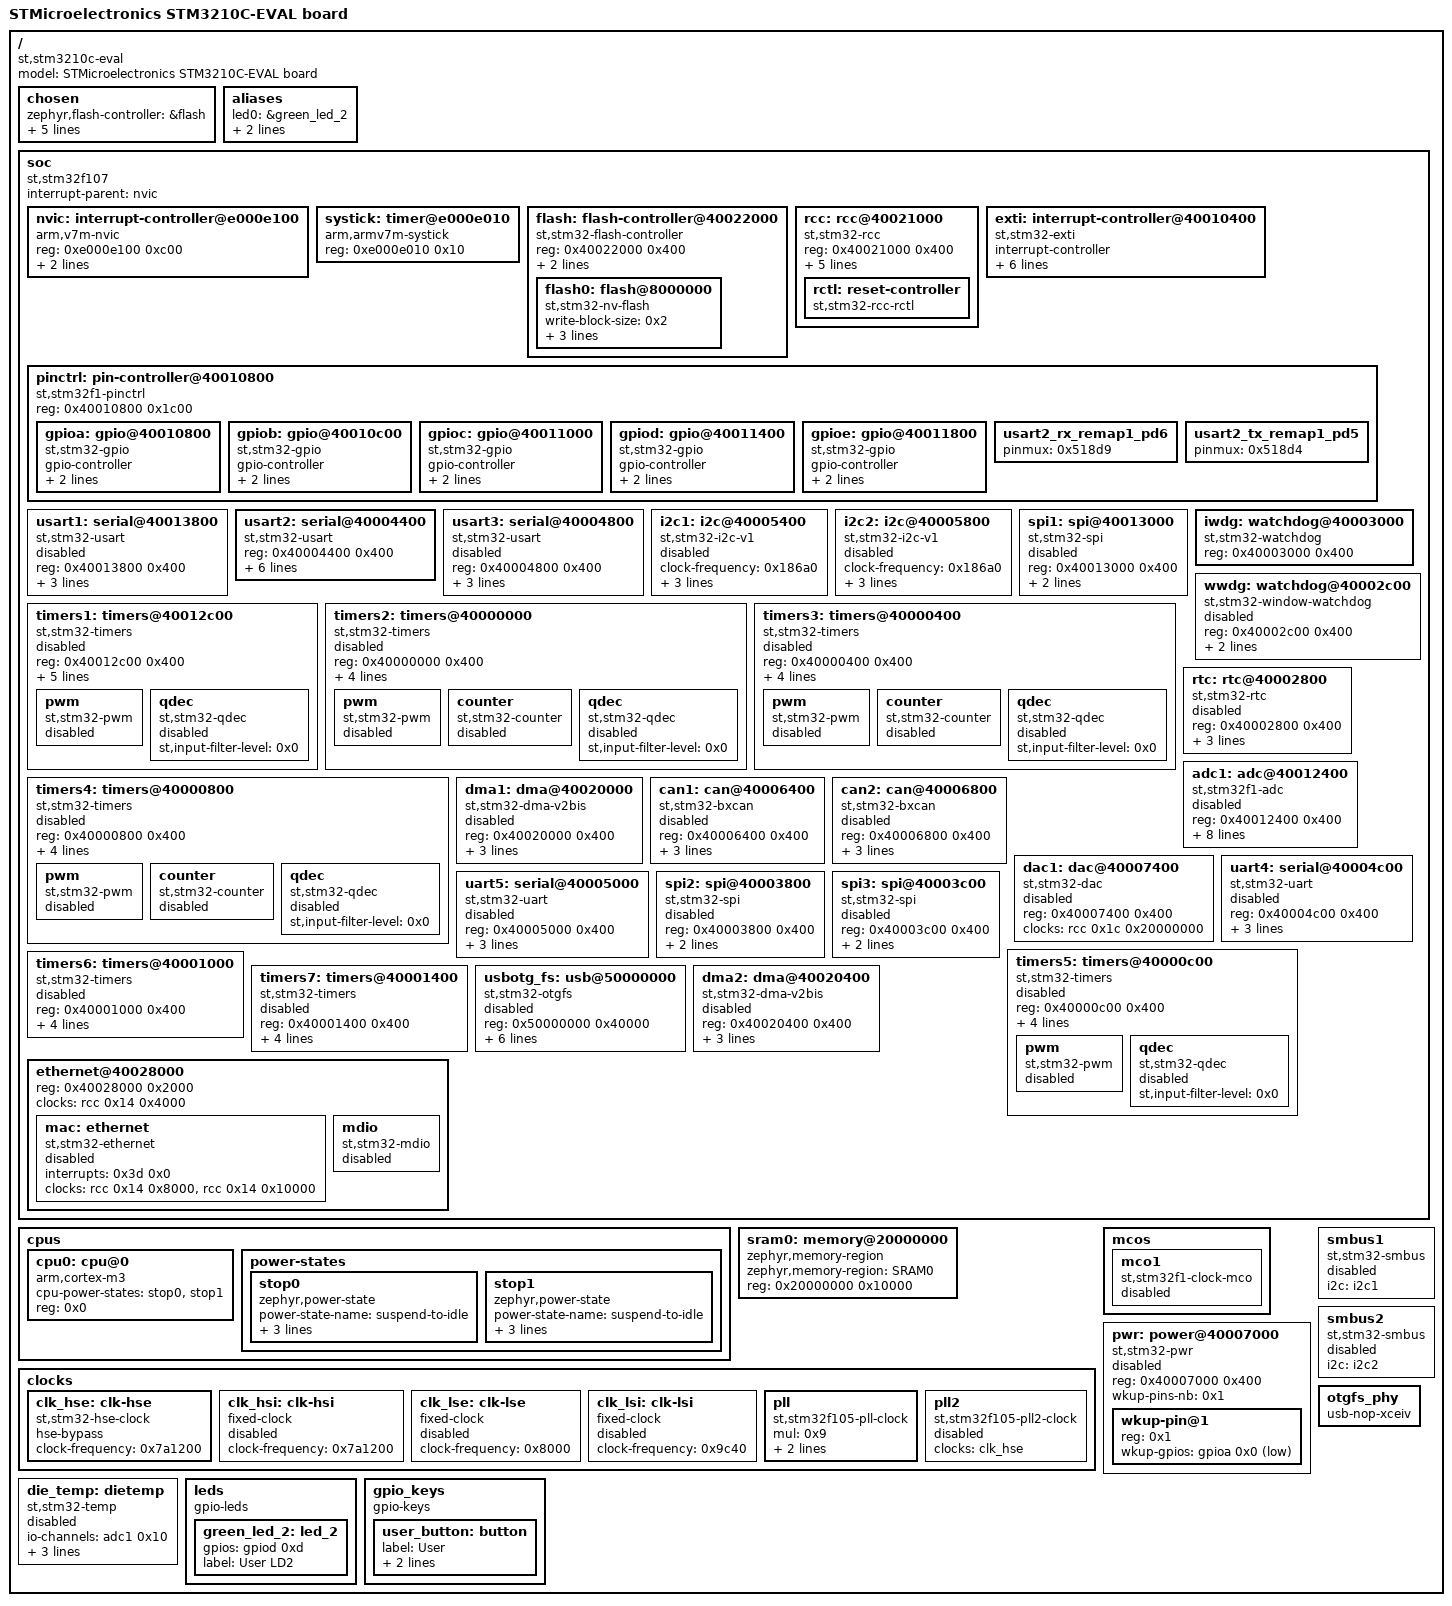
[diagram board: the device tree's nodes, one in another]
/dts-v1/;

/* node '/' defined in zephyr/dts/common/skeleton.dtsi:9 */
/ {
	#address-cells = < 0x1 >;                         /* in zephyr/dts/common/skeleton.dtsi:10 */
	#size-cells = < 0x1 >;                            /* in zephyr/dts/common/skeleton.dtsi:11 */
	model = "STMicroelectronics STM3210C-EVAL board"; /* in zephyr/boards/st/stm3210c_eval/stm3210c_eval.dts:13 */
	compatible = "st,stm3210c-eval";                  /* in zephyr/boards/st/stm3210c_eval/stm3210c_eval.dts:14 */

	/* node '/chosen' defined in zephyr/dts/common/skeleton.dtsi:13 */
	chosen {
		zephyr,flash-controller = &flash;  /* in zephyr/dts/arm/st/f1/stm32f1.dtsi:25 */
		zephyr,cortex-m-idle-timer = &rtc; /* in zephyr/dts/arm/st/f1/stm32f1.dtsi:26 */
		zephyr,console = &usart2;          /* in zephyr/boards/st/stm3210c_eval/stm3210c_eval.dts:17 */
		zephyr,shell-uart = &usart2;       /* in zephyr/boards/st/stm3210c_eval/stm3210c_eval.dts:18 */
		zephyr,sram = &sram0;              /* in zephyr/boards/st/stm3210c_eval/stm3210c_eval.dts:19 */
		zephyr,flash = &flash0;            /* in zephyr/boards/st/stm3210c_eval/stm3210c_eval.dts:20 */
	};

	/* node '/aliases' defined in zephyr/dts/common/skeleton.dtsi:15 */
	aliases {
		led0 = &green_led_2; /* in zephyr/boards/st/stm3210c_eval/stm3210c_eval.dts:43 */
		sw0 = &user_button;  /* in zephyr/boards/st/stm3210c_eval/stm3210c_eval.dts:44 */
		watchdog0 = &iwdg;   /* in zephyr/boards/st/stm3210c_eval/stm3210c_eval.dts:45 */
	};

	/* node '/soc' defined in zephyr/dts/arm/armv7-m.dtsi:6 */
	soc {
		#address-cells = < 0x1 >;     /* in zephyr/dts/arm/armv7-m.dtsi:7 */
		#size-cells = < 0x1 >;        /* in zephyr/dts/arm/armv7-m.dtsi:8 */
		interrupt-parent = < &nvic >; /* in zephyr/dts/arm/armv7-m.dtsi:10 */
		ranges;                       /* in zephyr/dts/arm/armv7-m.dtsi:11 */
		compatible = "st,stm32f107",
		             "st,stm32f1",
		             "simple-bus";    /* in zephyr/dts/arm/st/f1/stm32f107.dtsi:11 */

		/* node '/soc/interrupt-controller@e000e100' defined in zephyr/dts/arm/armv7-m.dtsi:13 */
		nvic: interrupt-controller@e000e100 {
			#address-cells = < 0x1 >;            /* in zephyr/dts/arm/armv7-m.dtsi:14 */
			compatible = "arm,v7m-nvic";         /* in zephyr/dts/arm/armv7-m.dtsi:15 */
			reg = < 0xe000e100 0xc00 >;          /* in zephyr/dts/arm/armv7-m.dtsi:16 */
			interrupt-controller;                /* in zephyr/dts/arm/armv7-m.dtsi:17 */
			#interrupt-cells = < 0x2 >;          /* in zephyr/dts/arm/armv7-m.dtsi:18 */
			arm,num-irq-priority-bits = < 0x4 >; /* in zephyr/dts/arm/st/f1/stm32f1.dtsi:461 */
			phandle = < 0x1 >;                   /* in zephyr/dts/arm/armv7-m.dtsi:10 */
		};

		/* node '/soc/timer@e000e010' defined in zephyr/dts/arm/armv7-m.dtsi:21 */
		systick: timer@e000e010 {
			compatible = "arm,armv7m-systick"; /* in zephyr/dts/arm/armv7-m.dtsi:22 */
			reg = < 0xe000e010 0x10 >;         /* in zephyr/dts/arm/armv7-m.dtsi:23 */
		};

		/* node '/soc/flash-controller@40022000' defined in zephyr/dts/arm/st/f1/stm32f1.dtsi:107 */
		flash: flash-controller@40022000 {
			compatible = "st,stm32-flash-controller",
			             "st,stm32f1-flash-controller"; /* in zephyr/dts/arm/st/f1/stm32f1.dtsi:108 */
			reg = < 0x40022000 0x400 >;                 /* in zephyr/dts/arm/st/f1/stm32f1.dtsi:109 */
			interrupts = < 0x3 0x0 >;                   /* in zephyr/dts/arm/st/f1/stm32f1.dtsi:110 */
			clocks = < &rcc 0x14 0x10 >;                /* in zephyr/dts/arm/st/f1/stm32f1.dtsi:111 */
			#address-cells = < 0x1 >;                   /* in zephyr/dts/arm/st/f1/stm32f1.dtsi:113 */
			#size-cells = < 0x1 >;                      /* in zephyr/dts/arm/st/f1/stm32f1.dtsi:114 */

			/* node '/soc/flash-controller@40022000/flash@8000000' defined in zephyr/dts/arm/st/f1/stm32f1.dtsi:116 */
			flash0: flash@8000000 {
				compatible = "st,stm32-nv-flash",
				             "soc-nv-flash";      /* in zephyr/dts/arm/st/f1/stm32f1.dtsi:117 */
				write-block-size = < 0x2 >;       /* in zephyr/dts/arm/st/f1/stm32f1.dtsi:119 */
				max-erase-time = < 0x28 >;        /* in zephyr/dts/arm/st/f1/stm32f1.dtsi:121 */
				erase-block-size = < 0x800 >;     /* in zephyr/dts/arm/st/f1/stm32f105.dtsi:34 */
				reg = < 0x8000000 0x40000 >;      /* in zephyr/dts/arm/st/f1/stm32f107Xc.dtsi:17 */
			};
		};

		/* node '/soc/rcc@40021000' defined in zephyr/dts/arm/st/f1/stm32f1.dtsi:125 */
		rcc: rcc@40021000 {
			compatible = "st,stm32-rcc";     /* in zephyr/dts/arm/st/f1/stm32f1.dtsi:126 */
			#clock-cells = < 0x2 >;          /* in zephyr/dts/arm/st/f1/stm32f1.dtsi:127 */
			reg = < 0x40021000 0x400 >;      /* in zephyr/dts/arm/st/f1/stm32f1.dtsi:128 */
			clocks = < &pll >;               /* in zephyr/boards/st/stm3210c_eval/stm3210c_eval.dts:63 */
			clock-frequency = < 0x44aa200 >; /* in zephyr/boards/st/stm3210c_eval/stm3210c_eval.dts:64 */
			ahb-prescaler = < 0x1 >;         /* in zephyr/boards/st/stm3210c_eval/stm3210c_eval.dts:65 */
			apb1-prescaler = < 0x2 >;        /* in zephyr/boards/st/stm3210c_eval/stm3210c_eval.dts:66 */
			apb2-prescaler = < 0x1 >;        /* in zephyr/boards/st/stm3210c_eval/stm3210c_eval.dts:67 */
			phandle = < 0x2 >;               /* in zephyr/dts/arm/st/f1/stm32f1.dtsi:111 */

			/* node '/soc/rcc@40021000/reset-controller' defined in zephyr/dts/arm/st/f1/stm32f1.dtsi:130 */
			rctl: reset-controller {
				compatible = "st,stm32-rcc-rctl"; /* in zephyr/dts/arm/st/f1/stm32f1.dtsi:131 */
				#reset-cells = < 0x1 >;           /* in zephyr/dts/arm/st/f1/stm32f1.dtsi:132 */
				phandle = < 0x4 >;                /* in zephyr/dts/arm/st/f1/stm32f1.dtsi:202 */
			};
		};

		/* node '/soc/interrupt-controller@40010400' defined in zephyr/dts/arm/st/f1/stm32f1.dtsi:136 */
		exti: interrupt-controller@40010400 {
			compatible = "st,stm32-exti";  /* in zephyr/dts/arm/st/f1/stm32f1.dtsi:137 */
			interrupt-controller;          /* in zephyr/dts/arm/st/f1/stm32f1.dtsi:138 */
			#interrupt-cells = < 0x1 >;    /* in zephyr/dts/arm/st/f1/stm32f1.dtsi:139 */
			#address-cells = < 0x0 >;      /* in zephyr/dts/arm/st/f1/stm32f1.dtsi:140 */
			reg = < 0x40010400 0x400 >;    /* in zephyr/dts/arm/st/f1/stm32f1.dtsi:141 */
			num-lines = < 0x20 >;          /* in zephyr/dts/arm/st/f1/stm32f1.dtsi:142 */
			interrupts = < 0x6 0x0 >,
			             < 0x7 0x0 >,
			             < 0x8 0x0 >,
			             < 0x9 0x0 >,
			             < 0xa 0x0 >,
			             < 0x17 0x0 >,
			             < 0x28 0x0 >;     /* in zephyr/dts/arm/st/f1/stm32f1.dtsi:143 */
			interrupt-names = "line0",
			                  "line1",
			                  "line2",
			                  "line3",
			                  "line4",
			                  "line5-9",
			                  "line10-15"; /* in zephyr/dts/arm/st/f1/stm32f1.dtsi:145 */
			line-ranges = < 0x0 0x1 >,
			              < 0x1 0x1 >,
			              < 0x2 0x1 >,
			              < 0x3 0x1 >,
			              < 0x4 0x1 >,
			              < 0x5 0x5 >,
			              < 0xa 0x6 >;     /* in zephyr/dts/arm/st/f1/stm32f1.dtsi:147 */
		};

		/* node '/soc/pin-controller@40010800' defined in zephyr/dts/arm/st/f1/stm32f1.dtsi:151 */
		pinctrl: pin-controller@40010800 {
			compatible = "st,stm32f1-pinctrl"; /* in zephyr/dts/arm/st/f1/stm32f1.dtsi:152 */
			#address-cells = < 0x1 >;          /* in zephyr/dts/arm/st/f1/stm32f1.dtsi:153 */
			#size-cells = < 0x1 >;             /* in zephyr/dts/arm/st/f1/stm32f1.dtsi:154 */
			reg = < 0x40010800 0x1c00 >;       /* in zephyr/dts/arm/st/f1/stm32f1.dtsi:155 */

			/* node '/soc/pin-controller@40010800/gpio@40010800' defined in zephyr/dts/arm/st/f1/stm32f1.dtsi:157 */
			gpioa: gpio@40010800 {
				compatible = "st,stm32-gpio"; /* in zephyr/dts/arm/st/f1/stm32f1.dtsi:158 */
				gpio-controller;              /* in zephyr/dts/arm/st/f1/stm32f1.dtsi:159 */
				#gpio-cells = < 0x2 >;        /* in zephyr/dts/arm/st/f1/stm32f1.dtsi:160 */
				reg = < 0x40010800 0x400 >;   /* in zephyr/dts/arm/st/f1/stm32f1.dtsi:161 */
				clocks = < &rcc 0x18 0x4 >;   /* in zephyr/dts/arm/st/f1/stm32f1.dtsi:162 */
				phandle = < 0xb >;            /* in zephyr/dts/arm/st/f1/stm32f1.dtsi:430 */
			};

			/* node '/soc/pin-controller@40010800/gpio@40010c00' defined in zephyr/dts/arm/st/f1/stm32f1.dtsi:165 */
			gpiob: gpio@40010c00 {
				compatible = "st,stm32-gpio"; /* in zephyr/dts/arm/st/f1/stm32f1.dtsi:166 */
				gpio-controller;              /* in zephyr/dts/arm/st/f1/stm32f1.dtsi:167 */
				#gpio-cells = < 0x2 >;        /* in zephyr/dts/arm/st/f1/stm32f1.dtsi:168 */
				reg = < 0x40010c00 0x400 >;   /* in zephyr/dts/arm/st/f1/stm32f1.dtsi:169 */
				clocks = < &rcc 0x18 0x8 >;   /* in zephyr/dts/arm/st/f1/stm32f1.dtsi:170 */
				phandle = < 0x10 >;           /* in zephyr/boards/st/stm3210c_eval/stm3210c_eval.dts:37 */
			};

			/* node '/soc/pin-controller@40010800/gpio@40011000' defined in zephyr/dts/arm/st/f1/stm32f1.dtsi:173 */
			gpioc: gpio@40011000 {
				compatible = "st,stm32-gpio"; /* in zephyr/dts/arm/st/f1/stm32f1.dtsi:174 */
				gpio-controller;              /* in zephyr/dts/arm/st/f1/stm32f1.dtsi:175 */
				#gpio-cells = < 0x2 >;        /* in zephyr/dts/arm/st/f1/stm32f1.dtsi:176 */
				reg = < 0x40011000 0x400 >;   /* in zephyr/dts/arm/st/f1/stm32f1.dtsi:177 */
				clocks = < &rcc 0x18 0x10 >;  /* in zephyr/dts/arm/st/f1/stm32f1.dtsi:178 */
			};

			/* node '/soc/pin-controller@40010800/gpio@40011400' defined in zephyr/dts/arm/st/f1/stm32f1.dtsi:181 */
			gpiod: gpio@40011400 {
				compatible = "st,stm32-gpio"; /* in zephyr/dts/arm/st/f1/stm32f1.dtsi:182 */
				gpio-controller;              /* in zephyr/dts/arm/st/f1/stm32f1.dtsi:183 */
				#gpio-cells = < 0x2 >;        /* in zephyr/dts/arm/st/f1/stm32f1.dtsi:184 */
				reg = < 0x40011400 0x400 >;   /* in zephyr/dts/arm/st/f1/stm32f1.dtsi:185 */
				clocks = < &rcc 0x18 0x20 >;  /* in zephyr/dts/arm/st/f1/stm32f1.dtsi:186 */
				phandle = < 0xf >;            /* in zephyr/boards/st/stm3210c_eval/stm3210c_eval.dts:27 */
			};

			/* node '/soc/pin-controller@40010800/gpio@40011800' defined in zephyr/dts/arm/st/f1/stm32f1.dtsi:189 */
			gpioe: gpio@40011800 {
				compatible = "st,stm32-gpio"; /* in zephyr/dts/arm/st/f1/stm32f1.dtsi:190 */
				gpio-controller;              /* in zephyr/dts/arm/st/f1/stm32f1.dtsi:191 */
				#gpio-cells = < 0x2 >;        /* in zephyr/dts/arm/st/f1/stm32f1.dtsi:192 */
				reg = < 0x40011800 0x400 >;   /* in zephyr/dts/arm/st/f1/stm32f1.dtsi:193 */
				clocks = < &rcc 0x18 0x40 >;  /* in zephyr/dts/arm/st/f1/stm32f1.dtsi:194 */
			};

			/* node '/soc/pin-controller@40010800/usart2_rx_remap1_pd6' defined in modules/hal/stm32/dts/st/f1/stm32f107v(b-c)tx-pinctrl.dtsi:1537 */
			usart2_rx_remap1_pd6: usart2_rx_remap1_pd6 {
				pinmux = < 0x518d9 >; /* in modules/hal/stm32/dts/st/f1/stm32f107v(b-c)tx-pinctrl.dtsi:1538 */
				phandle = < 0x6 >;    /* in zephyr/boards/st/stm3210c_eval/stm3210c_eval.dts:71 */
			};

			/* node '/soc/pin-controller@40010800/usart2_tx_remap1_pd5' defined in modules/hal/stm32/dts/st/f1/stm32f107v(b-c)tx-pinctrl.dtsi:1575 */
			usart2_tx_remap1_pd5: usart2_tx_remap1_pd5 {
				pinmux = < 0x518d4 >; /* in modules/hal/stm32/dts/st/f1/stm32f107v(b-c)tx-pinctrl.dtsi:1576 */
				phandle = < 0x5 >;    /* in zephyr/boards/st/stm3210c_eval/stm3210c_eval.dts:71 */
			};
		};

		/* node '/soc/serial@40013800' defined in zephyr/dts/arm/st/f1/stm32f1.dtsi:198 */
		usart1: serial@40013800 {
			compatible = "st,stm32-usart",
			             "st,stm32-uart";  /* in zephyr/dts/arm/st/f1/stm32f1.dtsi:199 */
			reg = < 0x40013800 0x400 >;    /* in zephyr/dts/arm/st/f1/stm32f1.dtsi:200 */
			clocks = < &rcc 0x18 0x4000 >; /* in zephyr/dts/arm/st/f1/stm32f1.dtsi:201 */
			resets = < &rctl 0x18e >;      /* in zephyr/dts/arm/st/f1/stm32f1.dtsi:202 */
			interrupts = < 0x25 0x0 >;     /* in zephyr/dts/arm/st/f1/stm32f1.dtsi:203 */
			status = "disabled";           /* in zephyr/dts/arm/st/f1/stm32f1.dtsi:204 */
		};

		/* node '/soc/serial@40004400' defined in zephyr/dts/arm/st/f1/stm32f1.dtsi:207 */
		usart2: serial@40004400 {
			compatible = "st,stm32-usart",
			             "st,stm32-uart";                                /* in zephyr/dts/arm/st/f1/stm32f1.dtsi:208 */
			reg = < 0x40004400 0x400 >;                                  /* in zephyr/dts/arm/st/f1/stm32f1.dtsi:209 */
			clocks = < &rcc 0x1c 0x20000 >;                              /* in zephyr/dts/arm/st/f1/stm32f1.dtsi:210 */
			resets = < &rctl 0x211 >;                                    /* in zephyr/dts/arm/st/f1/stm32f1.dtsi:211 */
			interrupts = < 0x26 0x0 >;                                   /* in zephyr/dts/arm/st/f1/stm32f1.dtsi:212 */
			pinctrl-0 = < &usart2_tx_remap1_pd5 &usart2_rx_remap1_pd6 >; /* in zephyr/boards/st/stm3210c_eval/stm3210c_eval.dts:71 */
			pinctrl-names = "default";                                   /* in zephyr/boards/st/stm3210c_eval/stm3210c_eval.dts:72 */
			current-speed = < 0x1c200 >;                                 /* in zephyr/boards/st/stm3210c_eval/stm3210c_eval.dts:73 */
			status = "okay";                                             /* in zephyr/boards/st/stm3210c_eval/stm3210c_eval.dts:74 */
		};

		/* node '/soc/serial@40004800' defined in zephyr/dts/arm/st/f1/stm32f1.dtsi:216 */
		usart3: serial@40004800 {
			compatible = "st,stm32-usart",
			             "st,stm32-uart";   /* in zephyr/dts/arm/st/f1/stm32f1.dtsi:217 */
			reg = < 0x40004800 0x400 >;     /* in zephyr/dts/arm/st/f1/stm32f1.dtsi:218 */
			clocks = < &rcc 0x1c 0x40000 >; /* in zephyr/dts/arm/st/f1/stm32f1.dtsi:219 */
			resets = < &rctl 0x212 >;       /* in zephyr/dts/arm/st/f1/stm32f1.dtsi:220 */
			interrupts = < 0x27 0x0 >;      /* in zephyr/dts/arm/st/f1/stm32f1.dtsi:221 */
			status = "disabled";            /* in zephyr/dts/arm/st/f1/stm32f1.dtsi:222 */
		};

		/* node '/soc/i2c@40005400' defined in zephyr/dts/arm/st/f1/stm32f1.dtsi:225 */
		i2c1: i2c@40005400 {
			compatible = "st,stm32-i2c-v1";  /* in zephyr/dts/arm/st/f1/stm32f1.dtsi:226 */
			clock-frequency = < 0x186a0 >;   /* in zephyr/dts/arm/st/f1/stm32f1.dtsi:227 */
			#address-cells = < 0x1 >;        /* in zephyr/dts/arm/st/f1/stm32f1.dtsi:228 */
			#size-cells = < 0x0 >;           /* in zephyr/dts/arm/st/f1/stm32f1.dtsi:229 */
			reg = < 0x40005400 0x400 >;      /* in zephyr/dts/arm/st/f1/stm32f1.dtsi:230 */
			clocks = < &rcc 0x1c 0x200000 >; /* in zephyr/dts/arm/st/f1/stm32f1.dtsi:231 */
			interrupts = < 0x1f 0x0 >,
			             < 0x20 0x0 >;       /* in zephyr/dts/arm/st/f1/stm32f1.dtsi:232 */
			interrupt-names = "event",
			                  "error";       /* in zephyr/dts/arm/st/f1/stm32f1.dtsi:233 */
			status = "disabled";             /* in zephyr/dts/arm/st/f1/stm32f1.dtsi:234 */
			phandle = < 0xd >;               /* in zephyr/dts/arm/st/f1/stm32f1.dtsi:447 */
		};

		/* node '/soc/i2c@40005800' defined in zephyr/dts/arm/st/f1/stm32f1.dtsi:237 */
		i2c2: i2c@40005800 {
			compatible = "st,stm32-i2c-v1";  /* in zephyr/dts/arm/st/f1/stm32f1.dtsi:238 */
			clock-frequency = < 0x186a0 >;   /* in zephyr/dts/arm/st/f1/stm32f1.dtsi:239 */
			#address-cells = < 0x1 >;        /* in zephyr/dts/arm/st/f1/stm32f1.dtsi:240 */
			#size-cells = < 0x0 >;           /* in zephyr/dts/arm/st/f1/stm32f1.dtsi:241 */
			reg = < 0x40005800 0x400 >;      /* in zephyr/dts/arm/st/f1/stm32f1.dtsi:242 */
			clocks = < &rcc 0x1c 0x400000 >; /* in zephyr/dts/arm/st/f1/stm32f1.dtsi:243 */
			interrupts = < 0x21 0x0 >,
			             < 0x22 0x0 >;       /* in zephyr/dts/arm/st/f1/stm32f1.dtsi:244 */
			interrupt-names = "event",
			                  "error";       /* in zephyr/dts/arm/st/f1/stm32f1.dtsi:245 */
			status = "disabled";             /* in zephyr/dts/arm/st/f1/stm32f1.dtsi:246 */
			phandle = < 0xe >;               /* in zephyr/dts/arm/st/f1/stm32f1.dtsi:455 */
		};

		/* node '/soc/spi@40013000' defined in zephyr/dts/arm/st/f1/stm32f1.dtsi:249 */
		spi1: spi@40013000 {
			compatible = "st,stm32-spi";   /* in zephyr/dts/arm/st/f1/stm32f1.dtsi:250 */
			#address-cells = < 0x1 >;      /* in zephyr/dts/arm/st/f1/stm32f1.dtsi:251 */
			#size-cells = < 0x0 >;         /* in zephyr/dts/arm/st/f1/stm32f1.dtsi:252 */
			reg = < 0x40013000 0x400 >;    /* in zephyr/dts/arm/st/f1/stm32f1.dtsi:253 */
			clocks = < &rcc 0x18 0x1000 >; /* in zephyr/dts/arm/st/f1/stm32f1.dtsi:254 */
			interrupts = < 0x23 0x5 >;     /* in zephyr/dts/arm/st/f1/stm32f1.dtsi:255 */
			status = "disabled";           /* in zephyr/dts/arm/st/f1/stm32f1.dtsi:256 */
		};

		/* node '/soc/watchdog@40003000' defined in zephyr/dts/arm/st/f1/stm32f1.dtsi:259 */
		iwdg: watchdog@40003000 {
			compatible = "st,stm32-watchdog"; /* in zephyr/dts/arm/st/f1/stm32f1.dtsi:260 */
			reg = < 0x40003000 0x400 >;       /* in zephyr/dts/arm/st/f1/stm32f1.dtsi:261 */
			status = "okay";                  /* in zephyr/boards/st/stm3210c_eval/stm3210c_eval.dts:78 */
		};

		/* node '/soc/watchdog@40002c00' defined in zephyr/dts/arm/st/f1/stm32f1.dtsi:265 */
		wwdg: watchdog@40002c00 {
			compatible = "st,stm32-window-watchdog"; /* in zephyr/dts/arm/st/f1/stm32f1.dtsi:266 */
			reg = < 0x40002c00 0x400 >;              /* in zephyr/dts/arm/st/f1/stm32f1.dtsi:267 */
			clocks = < &rcc 0x1c 0x800 >;            /* in zephyr/dts/arm/st/f1/stm32f1.dtsi:268 */
			interrupts = < 0x0 0x7 >;                /* in zephyr/dts/arm/st/f1/stm32f1.dtsi:269 */
			status = "disabled";                     /* in zephyr/dts/arm/st/f1/stm32f1.dtsi:270 */
		};

		/* node '/soc/timers@40012c00' defined in zephyr/dts/arm/st/f1/stm32f1.dtsi:273 */
		timers1: timers@40012c00 {
			compatible = "st,stm32-timers"; /* in zephyr/dts/arm/st/f1/stm32f1.dtsi:274 */
			reg = < 0x40012c00 0x400 >;     /* in zephyr/dts/arm/st/f1/stm32f1.dtsi:275 */
			clocks = < &rcc 0x18 0x800 >,
			         < &rcc 0x9 0xff >;     /* in zephyr/dts/arm/st/f1/stm32f1.dtsi:276 */
			resets = < &rctl 0x18b >;       /* in zephyr/dts/arm/st/f1/stm32f1.dtsi:278 */
			interrupts = < 0x18 0x0 >,
			             < 0x19 0x0 >,
			             < 0x1a 0x0 >,
			             < 0x1b 0x0 >;      /* in zephyr/dts/arm/st/f1/stm32f1.dtsi:279 */
			interrupt-names = "brk",
			                  "up",
			                  "trgcom",
			                  "cc";         /* in zephyr/dts/arm/st/f1/stm32f1.dtsi:280 */
			st,prescaler = < 0x0 >;         /* in zephyr/dts/arm/st/f1/stm32f1.dtsi:281 */
			status = "disabled";            /* in zephyr/dts/arm/st/f1/stm32f1.dtsi:282 */

			/* node '/soc/timers@40012c00/pwm' defined in zephyr/dts/arm/st/f1/stm32f1.dtsi:284 */
			pwm {
				compatible = "st,stm32-pwm"; /* in zephyr/dts/arm/st/f1/stm32f1.dtsi:285 */
				status = "disabled";         /* in zephyr/dts/arm/st/f1/stm32f1.dtsi:286 */
				#pwm-cells = < 0x3 >;        /* in zephyr/dts/arm/st/f1/stm32f1.dtsi:287 */
			};

			/* node '/soc/timers@40012c00/qdec' defined in zephyr/dts/arm/st/f1/stm32f1.dtsi:290 */
			qdec {
				compatible = "st,stm32-qdec";    /* in zephyr/dts/arm/st/f1/stm32f1.dtsi:291 */
				st,input-filter-level = < 0x0 >; /* in zephyr/dts/arm/st/f1/stm32f1.dtsi:292 */
				status = "disabled";             /* in zephyr/dts/arm/st/f1/stm32f1.dtsi:293 */
			};
		};

		/* node '/soc/timers@40000000' defined in zephyr/dts/arm/st/f1/stm32f1.dtsi:297 */
		timers2: timers@40000000 {
			compatible = "st,stm32-timers"; /* in zephyr/dts/arm/st/f1/stm32f1.dtsi:298 */
			reg = < 0x40000000 0x400 >;     /* in zephyr/dts/arm/st/f1/stm32f1.dtsi:299 */
			clocks = < &rcc 0x1c 0x1 >,
			         < &rcc 0x8 0xff >;     /* in zephyr/dts/arm/st/f1/stm32f1.dtsi:300 */
			resets = < &rctl 0x200 >;       /* in zephyr/dts/arm/st/f1/stm32f1.dtsi:302 */
			interrupts = < 0x1c 0x0 >;      /* in zephyr/dts/arm/st/f1/stm32f1.dtsi:303 */
			interrupt-names = "global";     /* in zephyr/dts/arm/st/f1/stm32f1.dtsi:304 */
			st,prescaler = < 0x0 >;         /* in zephyr/dts/arm/st/f1/stm32f1.dtsi:305 */
			status = "disabled";            /* in zephyr/dts/arm/st/f1/stm32f1.dtsi:306 */

			/* node '/soc/timers@40000000/pwm' defined in zephyr/dts/arm/st/f1/stm32f1.dtsi:308 */
			pwm {
				compatible = "st,stm32-pwm"; /* in zephyr/dts/arm/st/f1/stm32f1.dtsi:309 */
				status = "disabled";         /* in zephyr/dts/arm/st/f1/stm32f1.dtsi:310 */
				#pwm-cells = < 0x3 >;        /* in zephyr/dts/arm/st/f1/stm32f1.dtsi:311 */
			};

			/* node '/soc/timers@40000000/counter' defined in zephyr/dts/arm/st/f1/stm32f1.dtsi:314 */
			counter {
				compatible = "st,stm32-counter"; /* in zephyr/dts/arm/st/f1/stm32f1.dtsi:315 */
				status = "disabled";             /* in zephyr/dts/arm/st/f1/stm32f1.dtsi:316 */
			};

			/* node '/soc/timers@40000000/qdec' defined in zephyr/dts/arm/st/f1/stm32f1.dtsi:319 */
			qdec {
				compatible = "st,stm32-qdec";    /* in zephyr/dts/arm/st/f1/stm32f1.dtsi:320 */
				st,input-filter-level = < 0x0 >; /* in zephyr/dts/arm/st/f1/stm32f1.dtsi:321 */
				status = "disabled";             /* in zephyr/dts/arm/st/f1/stm32f1.dtsi:322 */
			};
		};

		/* node '/soc/timers@40000400' defined in zephyr/dts/arm/st/f1/stm32f1.dtsi:326 */
		timers3: timers@40000400 {
			compatible = "st,stm32-timers"; /* in zephyr/dts/arm/st/f1/stm32f1.dtsi:327 */
			reg = < 0x40000400 0x400 >;     /* in zephyr/dts/arm/st/f1/stm32f1.dtsi:328 */
			clocks = < &rcc 0x1c 0x2 >,
			         < &rcc 0x8 0xff >;     /* in zephyr/dts/arm/st/f1/stm32f1.dtsi:329 */
			resets = < &rctl 0x201 >;       /* in zephyr/dts/arm/st/f1/stm32f1.dtsi:331 */
			interrupts = < 0x1d 0x0 >;      /* in zephyr/dts/arm/st/f1/stm32f1.dtsi:332 */
			interrupt-names = "global";     /* in zephyr/dts/arm/st/f1/stm32f1.dtsi:333 */
			st,prescaler = < 0x0 >;         /* in zephyr/dts/arm/st/f1/stm32f1.dtsi:334 */
			status = "disabled";            /* in zephyr/dts/arm/st/f1/stm32f1.dtsi:335 */

			/* node '/soc/timers@40000400/pwm' defined in zephyr/dts/arm/st/f1/stm32f1.dtsi:337 */
			pwm {
				compatible = "st,stm32-pwm"; /* in zephyr/dts/arm/st/f1/stm32f1.dtsi:338 */
				status = "disabled";         /* in zephyr/dts/arm/st/f1/stm32f1.dtsi:339 */
				#pwm-cells = < 0x3 >;        /* in zephyr/dts/arm/st/f1/stm32f1.dtsi:340 */
			};

			/* node '/soc/timers@40000400/counter' defined in zephyr/dts/arm/st/f1/stm32f1.dtsi:343 */
			counter {
				compatible = "st,stm32-counter"; /* in zephyr/dts/arm/st/f1/stm32f1.dtsi:344 */
				status = "disabled";             /* in zephyr/dts/arm/st/f1/stm32f1.dtsi:345 */
			};

			/* node '/soc/timers@40000400/qdec' defined in zephyr/dts/arm/st/f1/stm32f1.dtsi:348 */
			qdec {
				compatible = "st,stm32-qdec";    /* in zephyr/dts/arm/st/f1/stm32f1.dtsi:349 */
				st,input-filter-level = < 0x0 >; /* in zephyr/dts/arm/st/f1/stm32f1.dtsi:350 */
				status = "disabled";             /* in zephyr/dts/arm/st/f1/stm32f1.dtsi:351 */
			};
		};

		/* node '/soc/timers@40000800' defined in zephyr/dts/arm/st/f1/stm32f1.dtsi:355 */
		timers4: timers@40000800 {
			compatible = "st,stm32-timers"; /* in zephyr/dts/arm/st/f1/stm32f1.dtsi:356 */
			reg = < 0x40000800 0x400 >;     /* in zephyr/dts/arm/st/f1/stm32f1.dtsi:357 */
			clocks = < &rcc 0x1c 0x4 >,
			         < &rcc 0x8 0xff >;     /* in zephyr/dts/arm/st/f1/stm32f1.dtsi:358 */
			resets = < &rctl 0x202 >;       /* in zephyr/dts/arm/st/f1/stm32f1.dtsi:360 */
			interrupts = < 0x1e 0x0 >;      /* in zephyr/dts/arm/st/f1/stm32f1.dtsi:361 */
			interrupt-names = "global";     /* in zephyr/dts/arm/st/f1/stm32f1.dtsi:362 */
			st,prescaler = < 0x0 >;         /* in zephyr/dts/arm/st/f1/stm32f1.dtsi:363 */
			status = "disabled";            /* in zephyr/dts/arm/st/f1/stm32f1.dtsi:364 */

			/* node '/soc/timers@40000800/pwm' defined in zephyr/dts/arm/st/f1/stm32f1.dtsi:366 */
			pwm {
				compatible = "st,stm32-pwm"; /* in zephyr/dts/arm/st/f1/stm32f1.dtsi:367 */
				status = "disabled";         /* in zephyr/dts/arm/st/f1/stm32f1.dtsi:368 */
				#pwm-cells = < 0x3 >;        /* in zephyr/dts/arm/st/f1/stm32f1.dtsi:369 */
			};

			/* node '/soc/timers@40000800/counter' defined in zephyr/dts/arm/st/f1/stm32f1.dtsi:372 */
			counter {
				compatible = "st,stm32-counter"; /* in zephyr/dts/arm/st/f1/stm32f1.dtsi:373 */
				status = "disabled";             /* in zephyr/dts/arm/st/f1/stm32f1.dtsi:374 */
			};

			/* node '/soc/timers@40000800/qdec' defined in zephyr/dts/arm/st/f1/stm32f1.dtsi:377 */
			qdec {
				compatible = "st,stm32-qdec";    /* in zephyr/dts/arm/st/f1/stm32f1.dtsi:378 */
				st,input-filter-level = < 0x0 >; /* in zephyr/dts/arm/st/f1/stm32f1.dtsi:379 */
				status = "disabled";             /* in zephyr/dts/arm/st/f1/stm32f1.dtsi:380 */
			};
		};

		/* node '/soc/rtc@40002800' defined in zephyr/dts/arm/st/f1/stm32f1.dtsi:384 */
		rtc: rtc@40002800 {
			compatible = "st,stm32-rtc";       /* in zephyr/dts/arm/st/f1/stm32f1.dtsi:385 */
			reg = < 0x40002800 0x400 >;        /* in zephyr/dts/arm/st/f1/stm32f1.dtsi:386 */
			interrupts = < 0x29 0x0 >;         /* in zephyr/dts/arm/st/f1/stm32f1.dtsi:387 */
			clocks = < &rcc 0x1c 0x10000000 >; /* in zephyr/dts/arm/st/f1/stm32f1.dtsi:388 */
			prescaler = < 0x8000 >;            /* in zephyr/dts/arm/st/f1/stm32f1.dtsi:389 */
			status = "disabled";               /* in zephyr/dts/arm/st/f1/stm32f1.dtsi:390 */
		};

		/* node '/soc/adc@40012400' defined in zephyr/dts/arm/st/f1/stm32f1.dtsi:393 */
		adc1: adc@40012400 {
			compatible = "st,stm32f1-adc",
			             "st,stm32-adc";                               /* in zephyr/dts/arm/st/f1/stm32f1.dtsi:394 */
			reg = < 0x40012400 0x400 >;                                /* in zephyr/dts/arm/st/f1/stm32f1.dtsi:395 */
			clocks = < &rcc 0x18 0x200 >;                              /* in zephyr/dts/arm/st/f1/stm32f1.dtsi:396 */
			clock-names = "adcx";                                      /* in zephyr/dts/arm/st/f1/stm32f1.dtsi:397 */
			interrupts = < 0x12 0x0 >;                                 /* in zephyr/dts/arm/st/f1/stm32f1.dtsi:398 */
			#io-channel-cells = < 0x1 >;                               /* in zephyr/dts/arm/st/f1/stm32f1.dtsi:399 */
			resolutions = < 0x6000ff >;                                /* in zephyr/dts/arm/st/f1/stm32f1.dtsi:400 */
			sampling-times = < 0x2 0x8 0xe 0x1d 0x2a 0x38 0x48 0xf0 >; /* in zephyr/dts/arm/st/f1/stm32f1.dtsi:401 */
			st,adc-sequencer = "programmable";                         /* in zephyr/dts/arm/st/f1/stm32f1.dtsi:402 */
			st,adc-oversampler = "none";                               /* in zephyr/dts/arm/st/f1/stm32f1.dtsi:403 */
			st,adc-internal-regulator = "none";                        /* in zephyr/dts/arm/st/f1/stm32f1.dtsi:404 */
			status = "disabled";                                       /* in zephyr/dts/arm/st/f1/stm32f1.dtsi:405 */
			phandle = < 0xc >;                                         /* in zephyr/dts/arm/st/f1/stm32f1.dtsi:436 */
		};

		/* node '/soc/dma@40020000' defined in zephyr/dts/arm/st/f1/stm32f1.dtsi:408 */
		dma1: dma@40020000 {
			compatible = "st,stm32-dma-v2bis";                                          /* in zephyr/dts/arm/st/f1/stm32f1.dtsi:409 */
			#dma-cells = < 0x2 >;                                                       /* in zephyr/dts/arm/st/f1/stm32f1.dtsi:410 */
			reg = < 0x40020000 0x400 >;                                                 /* in zephyr/dts/arm/st/f1/stm32f1.dtsi:411 */
			clocks = < &rcc 0x14 0x1 >;                                                 /* in zephyr/dts/arm/st/f1/stm32f1.dtsi:412 */
			interrupts = < 0xb 0x0 0xc 0x0 0xd 0x0 0xe 0x0 0xf 0x0 0x10 0x0 0x11 0x0 >; /* in zephyr/dts/arm/st/f1/stm32f1.dtsi:413 */
			status = "disabled";                                                        /* in zephyr/dts/arm/st/f1/stm32f1.dtsi:414 */
		};

		/* node '/soc/can@40006400' defined in zephyr/dts/arm/st/f1/stm32f105.dtsi:38 */
		can1: can@40006400 {
			compatible = "st,stm32-bxcan";    /* in zephyr/dts/arm/st/f1/stm32f105.dtsi:39 */
			reg = < 0x40006400 0x400 >;       /* in zephyr/dts/arm/st/f1/stm32f105.dtsi:40 */
			interrupts = < 0x13 0x0 >,
			             < 0x14 0x0 >,
			             < 0x15 0x0 >,
			             < 0x16 0x0 >;        /* in zephyr/dts/arm/st/f1/stm32f105.dtsi:41 */
			interrupt-names = "TX",
			                  "RX0",
			                  "RX1",
			                  "SCE";          /* in zephyr/dts/arm/st/f1/stm32f105.dtsi:42 */
			clocks = < &rcc 0x1c 0x2000000 >; /* in zephyr/dts/arm/st/f1/stm32f105.dtsi:43 */
			status = "disabled";              /* in zephyr/dts/arm/st/f1/stm32f105.dtsi:44 */
		};

		/* node '/soc/can@40006800' defined in zephyr/dts/arm/st/f1/stm32f105.dtsi:47 */
		can2: can@40006800 {
			compatible = "st,stm32-bxcan";    /* in zephyr/dts/arm/st/f1/stm32f105.dtsi:48 */
			reg = < 0x40006800 0x400 >;       /* in zephyr/dts/arm/st/f1/stm32f105.dtsi:49 */
			interrupts = < 0x3f 0x0 >,
			             < 0x40 0x0 >,
			             < 0x41 0x0 >,
			             < 0x42 0x0 >;        /* in zephyr/dts/arm/st/f1/stm32f105.dtsi:50 */
			interrupt-names = "TX",
			                  "RX0",
			                  "RX1",
			                  "SCE";          /* in zephyr/dts/arm/st/f1/stm32f105.dtsi:51 */
			clocks = < &rcc 0x1c 0x6000000 >; /* in zephyr/dts/arm/st/f1/stm32f105.dtsi:53 */
			status = "disabled";              /* in zephyr/dts/arm/st/f1/stm32f105.dtsi:54 */
		};

		/* node '/soc/dac@40007400' defined in zephyr/dts/arm/st/f1/stm32f105.dtsi:57 */
		dac1: dac@40007400 {
			compatible = "st,stm32-dac";       /* in zephyr/dts/arm/st/f1/stm32f105.dtsi:58 */
			reg = < 0x40007400 0x400 >;        /* in zephyr/dts/arm/st/f1/stm32f105.dtsi:59 */
			clocks = < &rcc 0x1c 0x20000000 >; /* in zephyr/dts/arm/st/f1/stm32f105.dtsi:60 */
			status = "disabled";               /* in zephyr/dts/arm/st/f1/stm32f105.dtsi:61 */
			#io-channel-cells = < 0x1 >;       /* in zephyr/dts/arm/st/f1/stm32f105.dtsi:62 */
		};

		/* node '/soc/serial@40004c00' defined in zephyr/dts/arm/st/f1/stm32f105.dtsi:65 */
		uart4: serial@40004c00 {
			compatible = "st,stm32-uart";   /* in zephyr/dts/arm/st/f1/stm32f105.dtsi:66 */
			reg = < 0x40004c00 0x400 >;     /* in zephyr/dts/arm/st/f1/stm32f105.dtsi:67 */
			clocks = < &rcc 0x1c 0x80000 >; /* in zephyr/dts/arm/st/f1/stm32f105.dtsi:68 */
			resets = < &rctl 0x213 >;       /* in zephyr/dts/arm/st/f1/stm32f105.dtsi:69 */
			interrupts = < 0x34 0x0 >;      /* in zephyr/dts/arm/st/f1/stm32f105.dtsi:70 */
			status = "disabled";            /* in zephyr/dts/arm/st/f1/stm32f105.dtsi:71 */
		};

		/* node '/soc/serial@40005000' defined in zephyr/dts/arm/st/f1/stm32f105.dtsi:74 */
		uart5: serial@40005000 {
			compatible = "st,stm32-uart";    /* in zephyr/dts/arm/st/f1/stm32f105.dtsi:75 */
			reg = < 0x40005000 0x400 >;      /* in zephyr/dts/arm/st/f1/stm32f105.dtsi:76 */
			clocks = < &rcc 0x1c 0x100000 >; /* in zephyr/dts/arm/st/f1/stm32f105.dtsi:77 */
			resets = < &rctl 0x214 >;        /* in zephyr/dts/arm/st/f1/stm32f105.dtsi:78 */
			interrupts = < 0x35 0x0 >;       /* in zephyr/dts/arm/st/f1/stm32f105.dtsi:79 */
			status = "disabled";             /* in zephyr/dts/arm/st/f1/stm32f105.dtsi:80 */
		};

		/* node '/soc/spi@40003800' defined in zephyr/dts/arm/st/f1/stm32f105.dtsi:83 */
		spi2: spi@40003800 {
			compatible = "st,stm32-spi";   /* in zephyr/dts/arm/st/f1/stm32f105.dtsi:84 */
			#address-cells = < 0x1 >;      /* in zephyr/dts/arm/st/f1/stm32f105.dtsi:85 */
			#size-cells = < 0x0 >;         /* in zephyr/dts/arm/st/f1/stm32f105.dtsi:86 */
			reg = < 0x40003800 0x400 >;    /* in zephyr/dts/arm/st/f1/stm32f105.dtsi:87 */
			clocks = < &rcc 0x1c 0x4000 >; /* in zephyr/dts/arm/st/f1/stm32f105.dtsi:88 */
			interrupts = < 0x24 0x5 >;     /* in zephyr/dts/arm/st/f1/stm32f105.dtsi:89 */
			status = "disabled";           /* in zephyr/dts/arm/st/f1/stm32f105.dtsi:90 */
		};

		/* node '/soc/spi@40003c00' defined in zephyr/dts/arm/st/f1/stm32f105.dtsi:93 */
		spi3: spi@40003c00 {
			compatible = "st,stm32-spi";   /* in zephyr/dts/arm/st/f1/stm32f105.dtsi:94 */
			#address-cells = < 0x1 >;      /* in zephyr/dts/arm/st/f1/stm32f105.dtsi:95 */
			#size-cells = < 0x0 >;         /* in zephyr/dts/arm/st/f1/stm32f105.dtsi:96 */
			reg = < 0x40003c00 0x400 >;    /* in zephyr/dts/arm/st/f1/stm32f105.dtsi:97 */
			clocks = < &rcc 0x1c 0x8000 >; /* in zephyr/dts/arm/st/f1/stm32f105.dtsi:98 */
			interrupts = < 0x33 0x5 >;     /* in zephyr/dts/arm/st/f1/stm32f105.dtsi:99 */
			status = "disabled";           /* in zephyr/dts/arm/st/f1/stm32f105.dtsi:100 */
		};

		/* node '/soc/timers@40000c00' defined in zephyr/dts/arm/st/f1/stm32f105.dtsi:103 */
		timers5: timers@40000c00 {
			compatible = "st,stm32-timers"; /* in zephyr/dts/arm/st/f1/stm32f105.dtsi:104 */
			reg = < 0x40000c00 0x400 >;     /* in zephyr/dts/arm/st/f1/stm32f105.dtsi:105 */
			clocks = < &rcc 0x1c 0x8 >,
			         < &rcc 0x8 0xff >;     /* in zephyr/dts/arm/st/f1/stm32f105.dtsi:106 */
			resets = < &rctl 0x203 >;       /* in zephyr/dts/arm/st/f1/stm32f105.dtsi:108 */
			interrupts = < 0x32 0x0 >;      /* in zephyr/dts/arm/st/f1/stm32f105.dtsi:109 */
			interrupt-names = "global";     /* in zephyr/dts/arm/st/f1/stm32f105.dtsi:110 */
			st,prescaler = < 0x0 >;         /* in zephyr/dts/arm/st/f1/stm32f105.dtsi:111 */
			status = "disabled";            /* in zephyr/dts/arm/st/f1/stm32f105.dtsi:112 */

			/* node '/soc/timers@40000c00/pwm' defined in zephyr/dts/arm/st/f1/stm32f105.dtsi:114 */
			pwm {
				compatible = "st,stm32-pwm"; /* in zephyr/dts/arm/st/f1/stm32f105.dtsi:115 */
				status = "disabled";         /* in zephyr/dts/arm/st/f1/stm32f105.dtsi:116 */
				#pwm-cells = < 0x3 >;        /* in zephyr/dts/arm/st/f1/stm32f105.dtsi:117 */
			};

			/* node '/soc/timers@40000c00/qdec' defined in zephyr/dts/arm/st/f1/stm32f105.dtsi:120 */
			qdec {
				compatible = "st,stm32-qdec";    /* in zephyr/dts/arm/st/f1/stm32f105.dtsi:121 */
				st,input-filter-level = < 0x0 >; /* in zephyr/dts/arm/st/f1/stm32f105.dtsi:122 */
				status = "disabled";             /* in zephyr/dts/arm/st/f1/stm32f105.dtsi:123 */
			};
		};

		/* node '/soc/timers@40001000' defined in zephyr/dts/arm/st/f1/stm32f105.dtsi:127 */
		timers6: timers@40001000 {
			compatible = "st,stm32-timers"; /* in zephyr/dts/arm/st/f1/stm32f105.dtsi:128 */
			reg = < 0x40001000 0x400 >;     /* in zephyr/dts/arm/st/f1/stm32f105.dtsi:129 */
			clocks = < &rcc 0x1c 0x10 >,
			         < &rcc 0x8 0xff >;     /* in zephyr/dts/arm/st/f1/stm32f105.dtsi:130 */
			resets = < &rctl 0x204 >;       /* in zephyr/dts/arm/st/f1/stm32f105.dtsi:132 */
			interrupts = < 0x36 0x0 >;      /* in zephyr/dts/arm/st/f1/stm32f105.dtsi:133 */
			interrupt-names = "global";     /* in zephyr/dts/arm/st/f1/stm32f105.dtsi:134 */
			st,prescaler = < 0x0 >;         /* in zephyr/dts/arm/st/f1/stm32f105.dtsi:135 */
			status = "disabled";            /* in zephyr/dts/arm/st/f1/stm32f105.dtsi:136 */
		};

		/* node '/soc/timers@40001400' defined in zephyr/dts/arm/st/f1/stm32f105.dtsi:139 */
		timers7: timers@40001400 {
			compatible = "st,stm32-timers"; /* in zephyr/dts/arm/st/f1/stm32f105.dtsi:140 */
			reg = < 0x40001400 0x400 >;     /* in zephyr/dts/arm/st/f1/stm32f105.dtsi:141 */
			clocks = < &rcc 0x1c 0x20 >,
			         < &rcc 0x8 0xff >;     /* in zephyr/dts/arm/st/f1/stm32f105.dtsi:142 */
			resets = < &rctl 0x205 >;       /* in zephyr/dts/arm/st/f1/stm32f105.dtsi:144 */
			interrupts = < 0x37 0x0 >;      /* in zephyr/dts/arm/st/f1/stm32f105.dtsi:145 */
			interrupt-names = "global";     /* in zephyr/dts/arm/st/f1/stm32f105.dtsi:146 */
			st,prescaler = < 0x0 >;         /* in zephyr/dts/arm/st/f1/stm32f105.dtsi:147 */
			status = "disabled";            /* in zephyr/dts/arm/st/f1/stm32f105.dtsi:148 */
		};

		/* node '/soc/usb@50000000' defined in zephyr/dts/arm/st/f1/stm32f105.dtsi:151 */
		usbotg_fs: usb@50000000 {
			compatible = "st,stm32-otgfs"; /* in zephyr/dts/arm/st/f1/stm32f105.dtsi:152 */
			reg = < 0x50000000 0x40000 >;  /* in zephyr/dts/arm/st/f1/stm32f105.dtsi:153 */
			interrupts = < 0x43 0x0 >;     /* in zephyr/dts/arm/st/f1/stm32f105.dtsi:154 */
			interrupt-names = "otgfs";     /* in zephyr/dts/arm/st/f1/stm32f105.dtsi:155 */
			num-bidir-endpoints = < 0x4 >; /* in zephyr/dts/arm/st/f1/stm32f105.dtsi:156 */
			ram-size = < 0x500 >;          /* in zephyr/dts/arm/st/f1/stm32f105.dtsi:157 */
			clocks = < &rcc 0x14 0x1000 >; /* in zephyr/dts/arm/st/f1/stm32f105.dtsi:158 */
			maximum-speed = "full-speed";  /* in zephyr/dts/arm/st/f1/stm32f105.dtsi:159 */
			phys = < &otgfs_phy >;         /* in zephyr/dts/arm/st/f1/stm32f105.dtsi:160 */
			status = "disabled";           /* in zephyr/dts/arm/st/f1/stm32f105.dtsi:161 */
		};

		/* node '/soc/dma@40020400' defined in zephyr/dts/arm/st/f1/stm32f107.dtsi:13 */
		dma2: dma@40020400 {
			compatible = "st,stm32-dma-v2bis";                             /* in zephyr/dts/arm/st/f1/stm32f107.dtsi:14 */
			#dma-cells = < 0x2 >;                                          /* in zephyr/dts/arm/st/f1/stm32f107.dtsi:15 */
			reg = < 0x40020400 0x400 >;                                    /* in zephyr/dts/arm/st/f1/stm32f107.dtsi:16 */
			clocks = < &rcc 0x14 0x2 >;                                    /* in zephyr/dts/arm/st/f1/stm32f107.dtsi:17 */
			interrupts = < 0x38 0x0 0x39 0x0 0x3a 0x0 0x3b 0x0 0x3c 0x0 >; /* in zephyr/dts/arm/st/f1/stm32f107.dtsi:18 */
			status = "disabled";                                           /* in zephyr/dts/arm/st/f1/stm32f107.dtsi:19 */
		};

		/* node '/soc/ethernet@40028000' defined in zephyr/dts/arm/st/f1/stm32f107.dtsi:22 */
		ethernet@40028000 {
			reg = < 0x40028000 0x2000 >;   /* in zephyr/dts/arm/st/f1/stm32f107.dtsi:23 */
			clock-names = "stm-eth";       /* in zephyr/dts/arm/st/f1/stm32f107.dtsi:24 */
			clocks = < &rcc 0x14 0x4000 >; /* in zephyr/dts/arm/st/f1/stm32f107.dtsi:25 */

			/* node '/soc/ethernet@40028000/ethernet' defined in zephyr/dts/arm/st/f1/stm32f107.dtsi:27 */
			mac: ethernet {
				compatible = "st,stm32-ethernet"; /* in zephyr/dts/arm/st/f1/stm32f107.dtsi:28 */
				interrupts = < 0x3d 0x0 >;        /* in zephyr/dts/arm/st/f1/stm32f107.dtsi:29 */
				clock-names = "mac-clk-tx",
				              "mac-clk-rx";       /* in zephyr/dts/arm/st/f1/stm32f107.dtsi:30 */
				clocks = < &rcc 0x14 0x8000 >,
				         < &rcc 0x14 0x10000 >;   /* in zephyr/dts/arm/st/f1/stm32f107.dtsi:31 */
				status = "disabled";              /* in zephyr/dts/arm/st/f1/stm32f107.dtsi:33 */
			};

			/* node '/soc/ethernet@40028000/mdio' defined in zephyr/dts/arm/st/f1/stm32f107.dtsi:36 */
			mdio: mdio {
				compatible = "st,stm32-mdio"; /* in zephyr/dts/arm/st/f1/stm32f107.dtsi:37 */
				#address-cells = < 0x1 >;     /* in zephyr/dts/arm/st/f1/stm32f107.dtsi:38 */
				#size-cells = < 0x0 >;        /* in zephyr/dts/arm/st/f1/stm32f107.dtsi:39 */
				status = "disabled";          /* in zephyr/dts/arm/st/f1/stm32f107.dtsi:40 */
			};
		};
	};

	/* node '/cpus' defined in zephyr/dts/arm/st/f1/stm32f1.dtsi:29 */
	cpus {
		#address-cells = < 0x1 >; /* in zephyr/dts/arm/st/f1/stm32f1.dtsi:30 */
		#size-cells = < 0x0 >;    /* in zephyr/dts/arm/st/f1/stm32f1.dtsi:31 */

		/* node '/cpus/cpu@0' defined in zephyr/dts/arm/st/f1/stm32f1.dtsi:33 */
		cpu0: cpu@0 {
			device_type = "cpu";                  /* in zephyr/dts/arm/st/f1/stm32f1.dtsi:34 */
			compatible = "arm,cortex-m3";         /* in zephyr/dts/arm/st/f1/stm32f1.dtsi:35 */
			cpu-power-states = < &stop0 &stop1 >; /* in zephyr/dts/arm/st/f1/stm32f1.dtsi:36 */
			reg = < 0x0 >;                        /* in zephyr/dts/arm/st/f1/stm32f1.dtsi:37 */
		};

		/* node '/cpus/power-states' defined in zephyr/dts/arm/st/f1/stm32f1.dtsi:40 */
		power-states {

			/* node '/cpus/power-states/stop0' defined in zephyr/dts/arm/st/f1/stm32f1.dtsi:41 */
			stop0: stop0 {
				compatible = "zephyr,power-state";    /* in zephyr/dts/arm/st/f1/stm32f1.dtsi:42 */
				power-state-name = "suspend-to-idle"; /* in zephyr/dts/arm/st/f1/stm32f1.dtsi:43 */
				substate-id = < 0x0 >;                /* in zephyr/dts/arm/st/f1/stm32f1.dtsi:44 */
				min-residency-us = < 0xf4240 >;       /* in zephyr/dts/arm/st/f1/stm32f1.dtsi:45 */
				exit-latency-us = < 0x190 >;          /* in zephyr/dts/arm/st/f1/stm32f1.dtsi:46 */
				phandle = < 0x8 >;                    /* in zephyr/dts/arm/st/f1/stm32f1.dtsi:36 */
			};

			/* node '/cpus/power-states/stop1' defined in zephyr/dts/arm/st/f1/stm32f1.dtsi:49 */
			stop1: stop1 {
				compatible = "zephyr,power-state";    /* in zephyr/dts/arm/st/f1/stm32f1.dtsi:50 */
				power-state-name = "suspend-to-idle"; /* in zephyr/dts/arm/st/f1/stm32f1.dtsi:51 */
				substate-id = < 0x1 >;                /* in zephyr/dts/arm/st/f1/stm32f1.dtsi:52 */
				min-residency-us = < 0xf4240 >;       /* in zephyr/dts/arm/st/f1/stm32f1.dtsi:53 */
				exit-latency-us = < 0x258 >;          /* in zephyr/dts/arm/st/f1/stm32f1.dtsi:54 */
				phandle = < 0x9 >;                    /* in zephyr/dts/arm/st/f1/stm32f1.dtsi:36 */
			};
		};
	};

	/* node '/memory@20000000' defined in zephyr/dts/arm/st/f1/stm32f1.dtsi:59 */
	sram0: memory@20000000 {
		compatible = "zephyr,memory-region",
		             "mmio-sram";            /* in zephyr/dts/arm/st/f1/stm32f1.dtsi:60 */
		zephyr,memory-region = "SRAM0";      /* in zephyr/dts/arm/st/f1/stm32f1.dtsi:61 */
		reg = < 0x20000000 0x10000 >;        /* in zephyr/dts/arm/st/f1/stm32f107Xc.dtsi:11 */
	};

	/* node '/clocks' defined in zephyr/dts/arm/st/f1/stm32f1.dtsi:64 */
	clocks {

		/* node '/clocks/clk-hse' defined in zephyr/dts/arm/st/f1/stm32f1.dtsi:65 */
		clk_hse: clk-hse {
			#clock-cells = < 0x0 >;            /* in zephyr/dts/arm/st/f1/stm32f1.dtsi:66 */
			compatible = "st,stm32-hse-clock"; /* in zephyr/dts/arm/st/f1/stm32f1.dtsi:67 */
			hse-bypass;                        /* in zephyr/boards/st/stm3210c_eval/stm3210c_eval.dts:50 */
			clock-frequency = < 0x7a1200 >;    /* in zephyr/boards/st/stm3210c_eval/stm3210c_eval.dts:51 */
			status = "okay";                   /* in zephyr/boards/st/stm3210c_eval/stm3210c_eval.dts:52 */
			phandle = < 0xa >;                 /* in zephyr/boards/st/stm3210c_eval/stm3210c_eval.dts:58 */
		};

		/* node '/clocks/clk-hsi' defined in zephyr/dts/arm/st/f1/stm32f1.dtsi:71 */
		clk_hsi: clk-hsi {
			#clock-cells = < 0x0 >;         /* in zephyr/dts/arm/st/f1/stm32f1.dtsi:72 */
			compatible = "fixed-clock";     /* in zephyr/dts/arm/st/f1/stm32f1.dtsi:73 */
			clock-frequency = < 0x7a1200 >; /* in zephyr/dts/arm/st/f1/stm32f1.dtsi:74 */
			status = "disabled";            /* in zephyr/dts/arm/st/f1/stm32f1.dtsi:75 */
		};

		/* node '/clocks/clk-lse' defined in zephyr/dts/arm/st/f1/stm32f1.dtsi:78 */
		clk_lse: clk-lse {
			#clock-cells = < 0x0 >;       /* in zephyr/dts/arm/st/f1/stm32f1.dtsi:79 */
			compatible = "fixed-clock";   /* in zephyr/dts/arm/st/f1/stm32f1.dtsi:80 */
			clock-frequency = < 0x8000 >; /* in zephyr/dts/arm/st/f1/stm32f1.dtsi:81 */
			status = "disabled";          /* in zephyr/dts/arm/st/f1/stm32f1.dtsi:82 */
		};

		/* node '/clocks/clk-lsi' defined in zephyr/dts/arm/st/f1/stm32f1.dtsi:85 */
		clk_lsi: clk-lsi {
			#clock-cells = < 0x0 >;       /* in zephyr/dts/arm/st/f1/stm32f1.dtsi:86 */
			compatible = "fixed-clock";   /* in zephyr/dts/arm/st/f1/stm32f1.dtsi:87 */
			clock-frequency = < 0x9c40 >; /* in zephyr/dts/arm/st/f1/stm32f1.dtsi:88 */
			status = "disabled";          /* in zephyr/dts/arm/st/f1/stm32f1.dtsi:89 */
		};

		/* node '/clocks/pll' defined in zephyr/dts/arm/st/f1/stm32f105.dtsi:15 */
		pll: pll {
			#clock-cells = < 0x0 >;                /* in zephyr/dts/arm/st/f1/stm32f105.dtsi:16 */
			compatible = "st,stm32f105-pll-clock"; /* in zephyr/dts/arm/st/f1/stm32f105.dtsi:17 */
			mul = < 0x9 >;                         /* in zephyr/boards/st/stm3210c_eval/stm3210c_eval.dts:56 */
			prediv = < 0x1 >;                      /* in zephyr/boards/st/stm3210c_eval/stm3210c_eval.dts:57 */
			clocks = < &clk_hse >;                 /* in zephyr/boards/st/stm3210c_eval/stm3210c_eval.dts:58 */
			status = "okay";                       /* in zephyr/boards/st/stm3210c_eval/stm3210c_eval.dts:59 */
			phandle = < 0x3 >;                     /* in zephyr/boards/st/stm3210c_eval/stm3210c_eval.dts:63 */
		};

		/* node '/clocks/pll2' defined in zephyr/dts/arm/st/f1/stm32f105.dtsi:21 */
		pll2: pll2 {
			#clock-cells = < 0x0 >;                 /* in zephyr/dts/arm/st/f1/stm32f105.dtsi:22 */
			compatible = "st,stm32f105-pll2-clock"; /* in zephyr/dts/arm/st/f1/stm32f105.dtsi:23 */
			clocks = < &clk_hse >;                  /* in zephyr/dts/arm/st/f1/stm32f105.dtsi:24 */
			status = "disabled";                    /* in zephyr/dts/arm/st/f1/stm32f105.dtsi:25 */
		};
	};

	/* node '/mcos' defined in zephyr/dts/arm/st/f1/stm32f1.dtsi:99 */
	mcos {

		/* node '/mcos/mco1' defined in zephyr/dts/arm/st/f1/stm32f1.dtsi:100 */
		mco1: mco1 {
			compatible = "st,stm32f1-clock-mco"; /* in zephyr/dts/arm/st/f1/stm32f1.dtsi:101 */
			status = "disabled";                 /* in zephyr/dts/arm/st/f1/stm32f1.dtsi:102 */
		};
	};

	/* node '/power@40007000' defined in zephyr/dts/arm/st/f1/stm32f1.dtsi:418 */
	pwr: power@40007000 {
		compatible = "st,stm32-pwr"; /* in zephyr/dts/arm/st/f1/stm32f1.dtsi:419 */
		reg = < 0x40007000 0x400 >;  /* in zephyr/dts/arm/st/f1/stm32f1.dtsi:420 */
		status = "disabled";         /* in zephyr/dts/arm/st/f1/stm32f1.dtsi:421 */
		wkup-pins-nb = < 0x1 >;      /* in zephyr/dts/arm/st/f1/stm32f1.dtsi:423 */
		#address-cells = < 0x1 >;    /* in zephyr/dts/arm/st/f1/stm32f1.dtsi:425 */
		#size-cells = < 0x0 >;       /* in zephyr/dts/arm/st/f1/stm32f1.dtsi:426 */

		/* node '/power@40007000/wkup-pin@1' defined in zephyr/dts/arm/st/f1/stm32f1.dtsi:428 */
		wkup-pin@1 {
			reg = < 0x1 >;                   /* in zephyr/dts/arm/st/f1/stm32f1.dtsi:429 */
			wkup-gpios = < &gpioa 0x0 0x1 >; /* in zephyr/dts/arm/st/f1/stm32f1.dtsi:430 */
		};
	};

	/* node '/dietemp' defined in zephyr/dts/arm/st/f1/stm32f1.dtsi:434 */
	die_temp: dietemp {
		compatible = "st,stm32-temp"; /* in zephyr/dts/arm/st/f1/stm32f1.dtsi:435 */
		io-channels = < &adc1 0x10 >; /* in zephyr/dts/arm/st/f1/stm32f1.dtsi:436 */
		status = "disabled";          /* in zephyr/dts/arm/st/f1/stm32f1.dtsi:437 */
		avgslope = "4.3";             /* in zephyr/dts/arm/st/f1/stm32f1.dtsi:438 */
		v25 = < 0x596 >;              /* in zephyr/dts/arm/st/f1/stm32f1.dtsi:439 */
		ntc;                          /* in zephyr/dts/arm/st/f1/stm32f1.dtsi:440 */
	};

	/* node '/smbus1' defined in zephyr/dts/arm/st/f1/stm32f1.dtsi:443 */
	smbus1: smbus1 {
		compatible = "st,stm32-smbus"; /* in zephyr/dts/arm/st/f1/stm32f1.dtsi:444 */
		#address-cells = < 0x1 >;      /* in zephyr/dts/arm/st/f1/stm32f1.dtsi:445 */
		#size-cells = < 0x0 >;         /* in zephyr/dts/arm/st/f1/stm32f1.dtsi:446 */
		i2c = < &i2c1 >;               /* in zephyr/dts/arm/st/f1/stm32f1.dtsi:447 */
		status = "disabled";           /* in zephyr/dts/arm/st/f1/stm32f1.dtsi:448 */
	};

	/* node '/smbus2' defined in zephyr/dts/arm/st/f1/stm32f1.dtsi:451 */
	smbus2: smbus2 {
		compatible = "st,stm32-smbus"; /* in zephyr/dts/arm/st/f1/stm32f1.dtsi:452 */
		#address-cells = < 0x1 >;      /* in zephyr/dts/arm/st/f1/stm32f1.dtsi:453 */
		#size-cells = < 0x0 >;         /* in zephyr/dts/arm/st/f1/stm32f1.dtsi:454 */
		i2c = < &i2c2 >;               /* in zephyr/dts/arm/st/f1/stm32f1.dtsi:455 */
		status = "disabled";           /* in zephyr/dts/arm/st/f1/stm32f1.dtsi:456 */
	};

	/* node '/otgfs_phy' defined in zephyr/dts/arm/st/f1/stm32f105.dtsi:165 */
	otgfs_phy: otgfs_phy {
		compatible = "usb-nop-xceiv"; /* in zephyr/dts/arm/st/f1/stm32f105.dtsi:166 */
		#phy-cells = < 0x0 >;         /* in zephyr/dts/arm/st/f1/stm32f105.dtsi:167 */
		phandle = < 0x7 >;            /* in zephyr/dts/arm/st/f1/stm32f105.dtsi:160 */
	};

	/* node '/leds' defined in zephyr/boards/st/stm3210c_eval/stm3210c_eval.dts:23 */
	leds {
		compatible = "gpio-leds"; /* in zephyr/boards/st/stm3210c_eval/stm3210c_eval.dts:24 */

		/* node '/leds/led_2' defined in zephyr/boards/st/stm3210c_eval/stm3210c_eval.dts:26 */
		green_led_2: led_2 {
			gpios = < &gpiod 0xd 0x0 >; /* in zephyr/boards/st/stm3210c_eval/stm3210c_eval.dts:27 */
			label = "User LD2";         /* in zephyr/boards/st/stm3210c_eval/stm3210c_eval.dts:28 */
		};
	};

	/* node '/gpio_keys' defined in zephyr/boards/st/stm3210c_eval/stm3210c_eval.dts:32 */
	gpio_keys {
		compatible = "gpio-keys"; /* in zephyr/boards/st/stm3210c_eval/stm3210c_eval.dts:33 */

		/* node '/gpio_keys/button' defined in zephyr/boards/st/stm3210c_eval/stm3210c_eval.dts:35 */
		user_button: button {
			label = "User";             /* in zephyr/boards/st/stm3210c_eval/stm3210c_eval.dts:36 */
			gpios = < &gpiob 0x9 0x1 >; /* in zephyr/boards/st/stm3210c_eval/stm3210c_eval.dts:37 */
			zephyr,code = < 0xb >;      /* in zephyr/boards/st/stm3210c_eval/stm3210c_eval.dts:38 */
		};
	};
};
